# YTM32B1MD1 register map
Vendor: YTMicro; File version: 1.4
CPU: CM33 r0p4, little endian, MPU, FPU, 2 interrupt priority bits
Registers are 32-bit, read-write, reset 0x0 unless marked. A register's access mark holds for its fields unless they carry their own. Offsets are from the block's base; [hi:lo] are bit positions; 'fields as' and 'values as' point back to an identical list.

## EMU0 — ECC Management Unit
Base 0x40072000; register names take the prefix EMU0_
0x00 EIGCR
  [0] GEN — This bit will enable or disable all error injection functions.
    0=Global error injection is disabled; 1=Global error injection is enabled
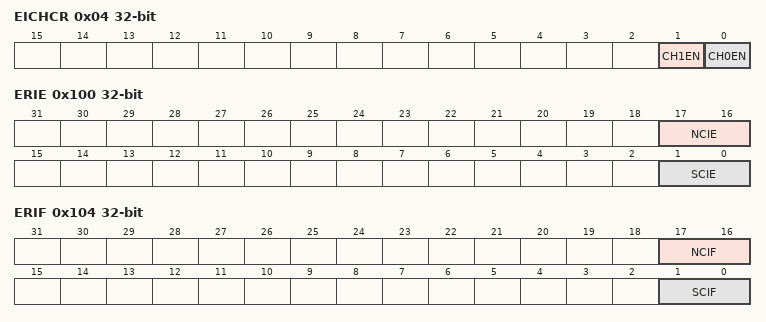
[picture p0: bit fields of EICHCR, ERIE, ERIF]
0x04 EICHCR
  [1] CH1EN — This field enable or disable channel 1 error injection function. Enable channel 1 error injection function should enable this field and EIGCR[GEN]. Any write to EICHD1_ADDR, EICHD1_CHKBIT, EICHD1_DATA register will clear this field. CH1EN is used for SRAM_U.
    0=Channel 1 error injection is disabled; 1=Channel 1 error injection is enabled
  [0] CH0EN — This field enable channel 0 error injection function. Enable channel 0 error injection function should enable this field and EIGCR[GEN]. Any write to EICHD0_ADDR, EICHD0_CHKBIT, EICHD0_DATA register will clear this field. CH0EN is used for SRAM_L.
    0=Channel 0 error injection is disabled; 1=Channel 0 error injection is enabled
0x10 EICHD0_ADDR
  [31:0] ADDR — This field defines which address will be injected error when read access. when the ADDR is not 0, error will be injected according to this field's value. if ADDR is 0, Error will be injected at all read access.
0x14 EICHD0_CHKBIT
  [6:0] CHKBIT — This field defines a bit-mapped mask that specifies whether the corresponding bit of the checkbit bus from the target SRAM should be inverted or remain unmodified. ewline 0b - The corresponding bit of the checkbit bus remains unmodified. ewline 1b - The corresponding bit of the checkbit bus is inverted.
0x18 EICHD0_DATA
  [31:0] DATA — This field defines a bit-mapped mask that specifies whether the corresponding bit of the read data bus from the target SRAM should be inverted or remain unmodified. ewline 0b - The corresponding bit of the databit bus remains unmodified. ewline 1b - The corresponding bit of the databit bus is inverted.
0x20 EICHD1_ADDR
  fields as EICHD0_ADDR
0x24 EICHD1_CHKBIT
  fields as EICHD0_CHKBIT
0x28 EICHD1_DATA
  fields as EICHD0_DATA
0x100 ERIE
  [17:16] NCIE — SRAM_L/U Non-Correctable error interrupt enable. bit 16 means SRAM_L, bit 17 means SRAM_U. ewline 0b - SRAM_L/U Non-Correctable Error interrupt is disabled ewline 1b - SRAM_L/U Non-Correctable Error interrupt is enabled
  [1:0] SCIE — SRAM_L/U Single correctable error interrupt enable, bit 0 means SRAM_L, bit 1 means SRAM_U. ewline 0b - SRAM_L/U Single Correctable Error interrupt is disabled ewline 1b - SRAM_L/U Single Correctable Error interrupt is enabled
0x104 ERIF
  [17:16] NCIF — SRAM_L/U Non-Correctable error interrupt flag. bit 16 means SRAM_L, bit 17 means SRAM_U. NCIF flag is kept when software reset but cleared when POR. 0b - SRAM_L/U Non-Correctable Error interrupt not detected 1b - SRAM_L/U Non-Correctable Error interrupt detected
  [1:0] SCIF — SRAM_L/U Single Correctable error interrupt flag, bit 0 means SRAM_L, bit 1 means SRAM_U. SCIF flag is kept when software reset but cleared when POR. 0b - SRAM_L/U Single Correctable Error interrupt not detected 1b - SRAM_L/U Single Correctable Error interrupt detected
0x110 ERINFO0_ADDR ro
  [31:0] ADDR — This field contains the faulting system address of the last recorded ECC event on SRAM_L/U.
0x114 ERINFO0_SYND ro
  [6:0] SYNDROME — This field contains the syndrome of the last recorded ECC event on SRAM_L/U
0x118 ERINFO0_CNT wo
  [7:0] CNT rw — For each correctable error event, the EMU increments this field's error count value until the counter reaches its maximum value 0xFF. CNT will not change once it reaches 0xFF and will not wrap even if error occurs. Read this field to determine the correctable error count value so far. Write zero to this field to reset the counter. Writing non-zero (or partial zero) values has no effect.
0x120 ERINFO1_ADDR ro
  fields as ERINFO0_ADDR
0x124 ERINFO1_SYND ro
  fields as ERINFO0_SYND
0x128 ERINFO1_CNT wo
  fields as ERINFO0_CNT
